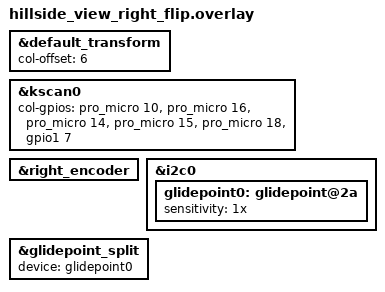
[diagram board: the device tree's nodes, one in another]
/*
 * Copyright (c) 2022 The ZMK Contributors
 *
 * SPDX-License-Identifier: MIT
 *
 * FLIPPED LAYOUT - RIGHT/PERIPHERAL side
 * - Uses original RIGHT PCB (flipped, MCU on top, sockets on opposite side)
 * - Cirque trackpad on I2C, relays to central via BLE split
 *
 * I2C pins from PCB (same for both top and bottom FFC - shared nets):
 * - SCL = P0.24 (D5)
 * - SDA = P1.0 (D6)
 * - DR  = P1.2
 */

#include "hillside_view.dtsi"

&default_transform {
    col-offset = <6>;
};

&kscan0 {
    /* Same column order as original RIGHT - flipping PCB doesn't change electrical routing */
    col-gpios
        = <&pro_micro 10 GPIO_ACTIVE_HIGH>
        , <&pro_micro 16 GPIO_ACTIVE_HIGH>
        , <&pro_micro 14 GPIO_ACTIVE_HIGH>
        , <&pro_micro 15 GPIO_ACTIVE_HIGH>
        , <&pro_micro 18 GPIO_ACTIVE_HIGH>
        , <&gpio1 7 GPIO_ACTIVE_HIGH>
        ;
};

&right_encoder {
    status = "okay";
};

/* Cirque trackpad on I2C */
&i2c0 {
    status = "okay";
    glidepoint0: glidepoint@2a {
        status = "okay";
        sensitivity = "1x";
    };
};

/* Connect the split input to the actual Cirque device */
&glidepoint_split {
    device = <&glidepoint0>;
};
